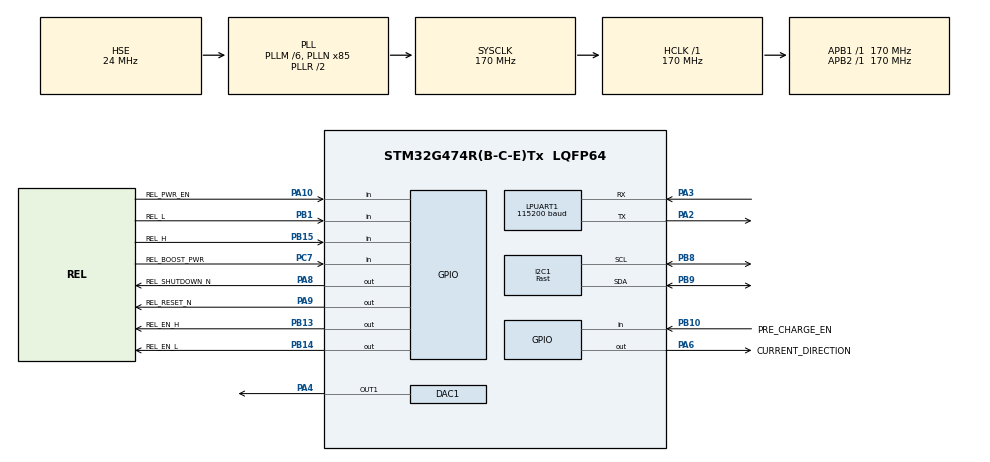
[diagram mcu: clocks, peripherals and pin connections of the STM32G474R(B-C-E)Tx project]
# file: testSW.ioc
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I2C1.I2C_Speed_Mode=I2C_Fast
I2C1.Timing=0x40621236
LPUART1.BaudRate=115200
Mcu.Family=STM32G4
Mcu.Name=STM32G474R(B-C-E)Tx
Mcu.Package=LQFP64
NVIC.PriorityGroup=NVIC_PRIORITYGROUP_4
PA10.GPIO_Label=REL_PWR_EN
PA10.Signal=GPIO_Input
PA2.Mode=Asynchronous
PA2.Signal=LPUART1_TX
PA3.Mode=Asynchronous
PA3.Signal=LPUART1_RX
PA4.Signal=COMP_DAC11_group
PA6.GPIO_Label=CURRENT_DIRECTION
PA6.Signal=GPIO_Output
PA8.GPIO_Label=REL_SHUTDOWN_N
PA8.GPIO_ModeDefaultOutputPP=GPIO_MODE_OUTPUT_OD
PA8.GPIO_PuPd=GPIO_NOPULL
PA8.PinState=GPIO_PIN_SET
PA8.Signal=GPIO_Output
PA9.GPIO_Label=REL_RESET_N
PA9.PinState=GPIO_PIN_SET
PA9.Signal=GPIO_Output
PB1.GPIO_Label=REL_L
PB1.Signal=GPIO_Input
PB10.GPIO_Label=PRE_CHARGE_EN
PB10.Signal=GPIO_Input
PB13.GPIO_Label=REL_EN_H
PB13.Signal=GPIO_Output
PB14.GPIO_Label=REL_EN_L
PB14.Signal=GPIO_Output
PB15.GPIO_Label=REL_H
PB15.Signal=GPIO_Input
PB8-BOOT0.GPIO_Pu=GPIO_PULLUP
PB8-BOOT0.Mode=I2C
PB8-BOOT0.Signal=I2C1_SCL
PB9.GPIO_Pu=GPIO_PULLUP
PB9.Mode=I2C
PB9.Signal=I2C1_SDA
PC7.GPIO_Label=REL_BOOST_PWR
PC7.Signal=GPIO_Input
PF0-OSC_IN.Mode=HSE-External-Oscillator
PF0-OSC_IN.Signal=RCC_OSC_IN
PF1-OSC_OUT.Mode=HSE-External-Oscillator
PF1-OSC_OUT.Signal=RCC_OSC_OUT
ProjectManager.HeapSize=0x1000
ProjectManager.StackSize=0x1000
ProjectManager.TargetToolchain=CMake
RCC.ADC12Freq_Value=170000000
RCC.ADC345Freq_Value=170000000
RCC.AHBFreq_Value=170000000
RCC.APB1Freq_Value=170000000
RCC.APB1TimFreq_Value=170000000
RCC.APB2Freq_Value=170000000
RCC.APB2TimFreq_Value=170000000
RCC.CortexFreq_Value=170000000
RCC.EXTERNAL_CLOCK_VALUE=12288000
RCC.HCLKFreq_Value=170000000
RCC.HSE_VALUE=24000000
RCC.HSI48_VALUE=48000000
RCC.HSI_VALUE=16000000
RCC.LSE_VALUE=32768
RCC.PLLM=RCC_PLLM_DIV6
RCC.PLLN=85
RCC.PLLSourceVirtual=RCC_PLLSOURCE_HSE
RCC.SYSCLKFreq_VALUE=170000000
RCC.SYSCLKSource=RCC_SYSCLKSOURCE_PLLCLK
RCC.USBFreq_Value=170000000
RCC.VCOOutputFreq_Value=340000000
SH.COMP_DAC11_group.0=DAC1_OUT1,DAC_OUT1
VP_SYS_VS_DBSignals.Mode=DisableDeadBatterySignals
board=custom

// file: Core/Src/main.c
/* USER CODE BEGIN Header */
/**
  ******************************************************************************
  * @file           : main.c
  * @brief          : Main program body
  ******************************************************************************
  * @attention
  *
  * Copyright (c) 2026 STMicroelectronics.
  * All rights reserved.
  *
  * This software is licensed under terms that can be found in the LICENSE file
  * in the root directory of this software component.
  * If no LICENSE file comes with this software, it is provided AS-IS.
  *
  ******************************************************************************
  */
/* USER CODE END Header */
#include "main.h"

/* USER CODE BEGIN Includes */
#include "appMain.h"

/* USER CODE END Includes */

DAC_HandleTypeDef hdac1;

I2C_HandleTypeDef hi2c1;

UART_HandleTypeDef hlpuart1;

void SystemClock_Config(void);
static void MX_GPIO_Init(void);
static void MX_LPUART1_UART_Init(void);
static void MX_I2C1_Init(void);
static void MX_DAC1_Init(void);

int main(void)
{

  /* MCU Configuration--------------------------------------------------------*/

  /* Reset of all peripherals, Initializes the Flash interface and the Systick. */
  HAL_Init();

  /* Configure the system clock */
  SystemClock_Config();

  /* Initialize all configured peripherals */
  MX_GPIO_Init();
  MX_LPUART1_UART_Init();
  MX_I2C1_Init();
  MX_DAC1_Init();
  /* USER CODE BEGIN 2 */
 App_Init();
  /* USER CODE END 2 */

  /* Infinite loop */
  /* USER CODE BEGIN WHILE */
  while (1)
  {
      App_Run();
    /* USER CODE END WHILE */

  }
}

void SystemClock_Config(void)
{
  RCC_OscInitTypeDef RCC_OscInitStruct = {0};
  RCC_ClkInitTypeDef RCC_ClkInitStruct = {0};

  /** Configure the main internal regulator output voltage
  */
  HAL_PWREx_ControlVoltageScaling(PWR_REGULATOR_VOLTAGE_SCALE1_BOOST);

  /** Initializes the RCC Oscillators according to the specified parameters
  * in the RCC_OscInitTypeDef structure.
  */
  RCC_OscInitStruct.OscillatorType = RCC_OSCILLATORTYPE_HSE;
  RCC_OscInitStruct.HSEState = RCC_HSE_ON;
  RCC_OscInitStruct.PLL.PLLState = RCC_PLL_ON;
  RCC_OscInitStruct.PLL.PLLSource = RCC_PLLSOURCE_HSE;
  RCC_OscInitStruct.PLL.PLLM = RCC_PLLM_DIV6;
  RCC_OscInitStruct.PLL.PLLN = 85;
  RCC_OscInitStruct.PLL.PLLP = RCC_PLLP_DIV2;
  RCC_OscInitStruct.PLL.PLLQ = RCC_PLLQ_DIV2;
  RCC_OscInitStruct.PLL.PLLR = RCC_PLLR_DIV2;
  if (HAL_RCC_OscConfig(&RCC_OscInitStruct) != HAL_OK)
  {
    Error_Handler();
  }

  /** Initializes the CPU, AHB and APB buses clocks
  */
  RCC_ClkInitStruct.ClockType = RCC_CLOCKTYPE_HCLK|RCC_CLOCKTYPE_SYSCLK
                              |RCC_CLOCKTYPE_PCLK1|RCC_CLOCKTYPE_PCLK2;
  RCC_ClkInitStruct.SYSCLKSource = RCC_SYSCLKSOURCE_PLLCLK;
  RCC_ClkInitStruct.AHBCLKDivider = RCC_SYSCLK_DIV1;
  RCC_ClkInitStruct.APB1CLKDivider = RCC_HCLK_DIV1;
  RCC_ClkInitStruct.APB2CLKDivider = RCC_HCLK_DIV1;

  if (HAL_RCC_ClockConfig(&RCC_ClkInitStruct, FLASH_LATENCY_4) != HAL_OK)
  {
    Error_Handler();
  }
}

static void MX_DAC1_Init(void)
{

  DAC_ChannelConfTypeDef sConfig = {0};

  /** DAC Initialization
  */
  hdac1.Instance = DAC1;
  if (HAL_DAC_Init(&hdac1) != HAL_OK)
  {
    Error_Handler();
  }

  /** DAC channel OUT1 config
  */
  sConfig.DAC_HighFrequency = DAC_HIGH_FREQUENCY_INTERFACE_MODE_AUTOMATIC;
  sConfig.DAC_DMADoubleDataMode = DISABLE;
  sConfig.DAC_SignedFormat = DISABLE;
  sConfig.DAC_SampleAndHold = DAC_SAMPLEANDHOLD_DISABLE;
  sConfig.DAC_Trigger = DAC_TRIGGER_NONE;
  sConfig.DAC_Trigger2 = DAC_TRIGGER_NONE;
  sConfig.DAC_OutputBuffer = DAC_OUTPUTBUFFER_ENABLE;
  sConfig.DAC_ConnectOnChipPeripheral = DAC_CHIPCONNECT_EXTERNAL;
  sConfig.DAC_UserTrimming = DAC_TRIMMING_FACTORY;
  if (HAL_DAC_ConfigChannel(&hdac1, &sConfig, DAC_CHANNEL_1) != HAL_OK)
  {
    Error_Handler();
  }

}

static void MX_I2C1_Init(void)
{

  hi2c1.Instance = I2C1;
  hi2c1.Init.Timing = 0x40621236;
  hi2c1.Init.OwnAddress1 = 0;
  hi2c1.Init.AddressingMode = I2C_ADDRESSINGMODE_7BIT;
  hi2c1.Init.DualAddressMode = I2C_DUALADDRESS_DISABLE;
  hi2c1.Init.OwnAddress2 = 0;
  hi2c1.Init.OwnAddress2Masks = I2C_OA2_NOMASK;
  hi2c1.Init.GeneralCallMode = I2C_GENERALCALL_DISABLE;
  hi2c1.Init.NoStretchMode = I2C_NOSTRETCH_DISABLE;
  if (HAL_I2C_Init(&hi2c1) != HAL_OK)
  {
    Error_Handler();
  }

  /** Configure Analogue filter
  */
  if (HAL_I2CEx_ConfigAnalogFilter(&hi2c1, I2C_ANALOGFILTER_ENABLE) != HAL_OK)
  {
    Error_Handler();
  }

  /** Configure Digital filter
  */
  if (HAL_I2CEx_ConfigDigitalFilter(&hi2c1, 0) != HAL_OK)
  {
    Error_Handler();
  }

}

static void MX_LPUART1_UART_Init(void)
{

  hlpuart1.Instance = LPUART1;
  hlpuart1.Init.BaudRate = 115200;
  hlpuart1.Init.WordLength = UART_WORDLENGTH_8B;
  hlpuart1.Init.StopBits = UART_STOPBITS_1;
  hlpuart1.Init.Parity = UART_PARITY_NONE;
  hlpuart1.Init.Mode = UART_MODE_TX_RX;
  hlpuart1.Init.HwFlowCtl = UART_HWCONTROL_NONE;
  hlpuart1.Init.OneBitSampling = UART_ONE_BIT_SAMPLE_DISABLE;
  hlpuart1.Init.ClockPrescaler = UART_PRESCALER_DIV1;
  hlpuart1.AdvancedInit.AdvFeatureInit = UART_ADVFEATURE_NO_INIT;
  if (HAL_UART_Init(&hlpuart1) != HAL_OK)
  {
    Error_Handler();
  }
  if (HAL_UARTEx_SetTxFifoThreshold(&hlpuart1, UART_TXFIFO_THRESHOLD_1_8) != HAL_OK)
  {
    Error_Handler();
  }
  if (HAL_UARTEx_SetRxFifoThreshold(&hlpuart1, UART_RXFIFO_THRESHOLD_1_8) != HAL_OK)
  {
    Error_Handler();
  }
  if (HAL_UARTEx_DisableFifoMode(&hlpuart1) != HAL_OK)
  {
    Error_Handler();
  }

}

static void MX_GPIO_Init(void)
{
  GPIO_InitTypeDef GPIO_InitStruct = {0};

  /* GPIO Ports Clock Enable */
  __HAL_RCC_GPIOF_CLK_ENABLE();
  __HAL_RCC_GPIOA_CLK_ENABLE();
  __HAL_RCC_GPIOB_CLK_ENABLE();
  __HAL_RCC_GPIOC_CLK_ENABLE();

  /*Configure GPIO pin Output Level */
  HAL_GPIO_WritePin(CURRENT_DIRECTION_GPIO_Port, CURRENT_DIRECTION_Pin, GPIO_PIN_RESET);

  /*Configure GPIO pin Output Level */
  HAL_GPIO_WritePin(GPIOB, REL_EN_H_Pin|REL_EN_L_Pin, GPIO_PIN_RESET);

  /*Configure GPIO pin Output Level */
  HAL_GPIO_WritePin(GPIOA, REL_SHUTDOWN_N_Pin|REL_RESET_N_Pin, GPIO_PIN_SET);

  /*Configure GPIO pins : CURRENT_DIRECTION_Pin REL_RESET_N_Pin */
  GPIO_InitStruct.Pin = CURRENT_DIRECTION_Pin|REL_RESET_N_Pin;
  GPIO_InitStruct.Mode = GPIO_MODE_OUTPUT_PP;
  GPIO_InitStruct.Pull = GPIO_NOPULL;
  GPIO_InitStruct.Speed = GPIO_SPEED_FREQ_LOW;
  HAL_GPIO_Init(GPIOA, &GPIO_InitStruct);

  /*Configure GPIO pins : REL_L_Pin PRE_CHARGE_EN_Pin REL_H_Pin */
  GPIO_InitStruct.Pin = REL_L_Pin|PRE_CHARGE_EN_Pin|REL_H_Pin;
  GPIO_InitStruct.Mode = GPIO_MODE_INPUT;
  GPIO_InitStruct.Pull = GPIO_NOPULL;
  HAL_GPIO_Init(GPIOB, &GPIO_InitStruct);

  /*Configure GPIO pins : REL_EN_H_Pin REL_EN_L_Pin */
  GPIO_InitStruct.Pin = REL_EN_H_Pin|REL_EN_L_Pin;
  GPIO_InitStruct.Mode = GPIO_MODE_OUTPUT_PP;
  GPIO_InitStruct.Pull = GPIO_NOPULL;
  GPIO_InitStruct.Speed = GPIO_SPEED_FREQ_LOW;
  HAL_GPIO_Init(GPIOB, &GPIO_InitStruct);

  /*Configure GPIO pin : REL_BOOST_PWR_Pin */
  GPIO_InitStruct.Pin = REL_BOOST_PWR_Pin;
  GPIO_InitStruct.Mode = GPIO_MODE_INPUT;
  GPIO_InitStruct.Pull = GPIO_NOPULL;
  HAL_GPIO_Init(REL_BOOST_PWR_GPIO_Port, &GPIO_InitStruct);

  /*Configure GPIO pin : REL_SHUTDOWN_N_Pin */
  GPIO_InitStruct.Pin = REL_SHUTDOWN_N_Pin;
  GPIO_InitStruct.Mode = GPIO_MODE_OUTPUT_OD;
  GPIO_InitStruct.Pull = GPIO_NOPULL;
  GPIO_InitStruct.Speed = GPIO_SPEED_FREQ_LOW;
  HAL_GPIO_Init(REL_SHUTDOWN_N_GPIO_Port, &GPIO_InitStruct);

  /*Configure GPIO pin : REL_PWR_EN_Pin */
  GPIO_InitStruct.Pin = REL_PWR_EN_Pin;
  GPIO_InitStruct.Mode = GPIO_MODE_INPUT;
  GPIO_InitStruct.Pull = GPIO_NOPULL;
  HAL_GPIO_Init(REL_PWR_EN_GPIO_Port, &GPIO_InitStruct);

}

void Error_Handler(void)
{
  __disable_irq();
  while (1)
  {
  }
}
